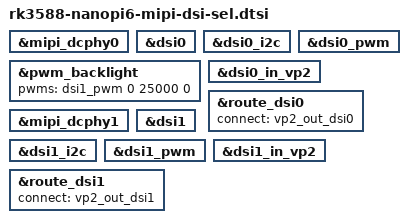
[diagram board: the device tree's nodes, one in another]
// SPDX-License-Identifier: (GPL-2.0+ OR MIT)
/*
 * Copyright (c) 2024 FriendlyElec Computer Tech. Co., Ltd.
 * (http://www.friendlyelec.com)
 */


&mipi_dcphy0 {
	status = "okay";
};

&dsi0 {
	status = "okay";
};

&dsi0_i2c {
	status = "okay";
};

&dsi0_pwm {
	status = "okay";
};

&pwm_backlight {
	status = "okay";
	pwms = <&dsi0_pwm 0 25000 0>;
};

&dsi0_in_vp2 {
	status = "okay";
};

&route_dsi0 {
	status = "okay";
	connect = <&vp2_out_dsi0>;
};

&mipi_dcphy1 {
	status = "okay";
};

&dsi1 {
	status = "okay";
};

&dsi1_i2c {
	status = "okay";
};

&dsi1_pwm {
	status = "okay";
};

&pwm_backlight {
	status = "okay";
	pwms = <&dsi1_pwm 0 25000 0>;
};

&dsi1_in_vp2 {
	status = "okay";
};

&route_dsi1 {
	status = "okay";
	connect = <&vp2_out_dsi1>;
};
